# M058SAN_v1 register map
File version: 1.0
M058SAN_v1 SVD file
Registers are 32-bit, read-write, reset 0x0 unless marked. A register's access mark holds for its fields unless they carry their own. Offsets are from the block's base; lines under a group give offsets from that group; [hi:lo] are bit positions; {n}, {i} and the like mark numbered series; 'fields as' and 'values as' point back to an identical list; <NAME> marks a mode.

## Memory map
0x40004000 WDT size 0x4 — WDT Register Map
0x40004100 WWDT size 0x10 — WWDT Register Map
0x40010000 TMR01 blocks up to offset 0x3C — TMR Register Map
0x40020000 I2C0 blocks up to offset 0x44 — I2C Register Map
0x40030000 SPI0 blocks up to offset 0x48 — SPI Register Map
0x40040000 PWM blocks up to offset 0xA4 — PWM Register Map
0x40050000 UART size 0x34 — UART Register Map
0x400E0000 ADC blocks up to offset 0x48 — ADC Register Map
0x40110000 TMR23 blocks up to offset 0x3C — TMR Register Map
0x40120000 I2C1 blocks up to offset 0x44 — I2C Register Map
0x50000000 GCR blocks up to offset 0x104 — GCR Register Map
0x50000200 CLK size 0x28 — CLK Register Map
0x50000300 INT size 0x88 — INT Register Map
0x50004000 GP blocks up to offset 0x3C8 — GP Register Map
0x5000C000 FMC size 0x1C — FMC Register Map
0xE000E000 SCS blocks up to offset 0xD24 — SCS Register Map

## INT — INT Register Map
Base 0x50000300
0x00 IRQ0_SRC ro reset not defined — IRQ0 (BOD) interrupt source identity
  [3:0] INT_SRC — Interrupt Source. Define the interrupt sources for interrupt event.
0x04 IRQ1_SRC ro reset not defined — IRQ1 (WDT) interrupt source identity
  fields as IRQ0_SRC
0x08 IRQ2_SRC ro reset not defined — IRQ2 (EINT0) interrupt source identity
  fields as IRQ0_SRC
0x0C IRQ3_SRC ro reset not defined — IRQ3 (EINT1) interrupt source identity
  fields as IRQ0_SRC
0x10 IRQ4_SRC ro reset not defined — IRQ4 (P0/1) interrupt source identity
  fields as IRQ0_SRC
0x14 IRQ5_SRC ro reset not defined — IRQ5 (P2/3/4) interrupt source identity
  fields as IRQ0_SRC
0x18 IRQ6_SRC ro reset not defined — IRQ6 (PWM) interrupt source identity
  fields as IRQ0_SRC
0x1C IRQ7_SRC ro reset not defined — Reserved
  fields as IRQ0_SRC
{0x0+4i} IRQ{i}_SRC ro reset not defined (i=8..11) — IRQ{i} (TMR{i-8}) interrupt source identity
  fields as IRQ0_SRC
0x30 IRQ12_SRC ro reset not defined — IRQ12 (URT) interrupt source identity
  fields as IRQ0_SRC
{0x0+4i} IRQ{i}_SRC ro reset not defined (i=13..15) — Reserved
  fields as IRQ0_SRC
0x40 IRQ16_SRC ro reset not defined — IRQ16 (P5) interrupt source identity
  fields as IRQ0_SRC
0x44 IRQ17_SRC ro reset not defined — IRQ17 (P6/7) interrupt source identity
  fields as IRQ0_SRC
0x48 IRQ18_SRC ro reset not defined — IRQ18 (I2C0) interrupt source identity
  fields as IRQ0_SRC
0x4C IRQ19_SRC ro reset not defined — IRQ19 (I2C1) interrupt source identity
  fields as IRQ0_SRC
0x50 IRQ20_SRC ro reset not defined — IRQ20 (PWMCAP0) interrupt source identity
  fields as IRQ0_SRC
0x54 IRQ21_SRC ro reset not defined — IRQ21(PWMCAP1) interrupt source identity
  fields as IRQ0_SRC
0x58 IRQ22_SRC ro reset not defined — IRQ22 (PWMCAP2) interrupt source identity
  fields as IRQ0_SRC
0x5C IRQ23_SRC ro reset not defined — IRQ23 (PWMCAP3) interrupt source identity
  fields as IRQ0_SRC
{0x0+4i} IRQ{i}_SRC ro reset not defined (i=24..27) — Reserved
  fields as IRQ0_SRC
0x70 IRQ28_SRC ro reset not defined — IRQ28 (PWRWU) interrupt source identity
  fields as IRQ0_SRC
{0x0+4i} IRQ{i}_SRC ro reset not defined (i=29..31) — Reserved
  fields as IRQ0_SRC
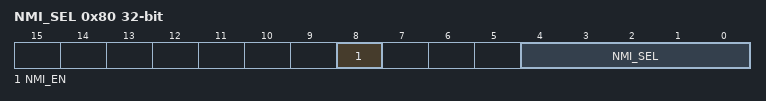
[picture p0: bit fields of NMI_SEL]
0x80 NMI_SEL — NMI source interrupt select control register
  [8] NMI_EN — NMI interrupt enable (write-protection bit). This bit is the protected bit. It means programming this needs to write "59h", "16h", "88h" to address 0x5000_0100 to disable register protection. Reference the register REGWRPROT at address GCR_BA+0x100
    0=Disable NMI interrupt; 1=Enable NMI interrupt
  [4:0] NMI_SEL — NMI interrupt source selection. The NMI interrupt to Cortex-M0 can be selected from one of the interrupt[31:0]. The NMI_SEL bit[4:0] used to select the NMI interrupt source
0x84 MCU_IRQ — MCU Interrupt Request Source Register
  [31:0] MCU_IRQ — MCU IRQ Source Register. The MCU_IRQ collects all the interrupts from the peripherals and generates the synchronous interrupt to Cortex-M0 core. There are two modes to generate interrupt to Cortex-M0, the normal mode and test mode. The MCU_IRQ collects all interrupts from each peripheral and synchronizes them then interrupts the Cortex-M0. When the MCU_IRQ[n] is "0", set MCU_IRQ[n] "1" will generate an interrupt to Cortex_M0 NVIC[n]. When the MCU_IRQ[n] is "1" (mean an interrupt is assert), set 1 to the MCU_IRQ[n] will clear the interrupt and set MCU_IRQ[n] "0" : no any effect
